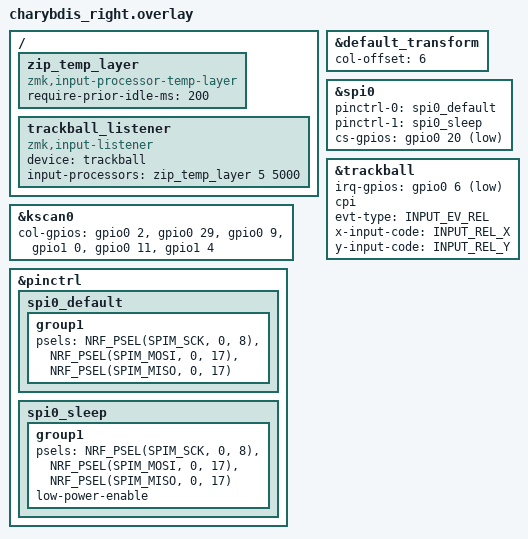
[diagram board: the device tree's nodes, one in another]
/*
 * Copyright (c) 2020 ZMK Contributors
 *
 * SPDX-License-Identifier: MIT
 */
 
#include "charybdis.dtsi"
// ★AML (オートマウスレイヤー) と KEYMAP_P マクロに必要な include を追加
#include <input/processors.dtsi>
#include <dt-bindings/zmk/matrix_transform.h>

&default_transform {
    col-offset = <6>;
};

&kscan0 {
	col-gpios
		= <&gpio0 2 (GPIO_ACTIVE_HIGH | GPIO_PULL_DOWN)>
		, <&gpio0 29 (GPIO_ACTIVE_HIGH | GPIO_PULL_DOWN)>
		, <&gpio0 9 (GPIO_ACTIVE_HIGH | GPIO_PULL_DOWN)>
		, <&gpio1 0  (GPIO_ACTIVE_HIGH | GPIO_PULL_DOWN)>
		, <&gpio0 11 (GPIO_ACTIVE_HIGH | GPIO_PULL_DOWN)>
		, <&gpio1 4  (GPIO_ACTIVE_HIGH | GPIO_PULL_DOWN)>
		;
};

// trackball bus
&spi0 {
	status = "okay";
    pinctrl-0 = <&spi0_default>;
    pinctrl-1 = <&spi0_sleep>;
    pinctrl-names = "default", "sleep";
	cs-gpios = <&gpio0 20 GPIO_ACTIVE_LOW>;
};

&pinctrl {
    spi0_default: spi0_default {
        group1 {
            psels = <NRF_PSEL(SPIM_SCK, 0, 8)>,
                    <NRF_PSEL(SPIM_MOSI, 0, 17)>,
                    <NRF_PSEL(SPIM_MISO, 0, 17)>;
        };
    };

    spi0_sleep: spi0_sleep {
        group1 {
            psels = <NRF_PSEL(SPIM_SCK, 0, 8)>,
                    <NRF_PSEL(SPIM_MOSI, 0, 17)>,
                    <NRF_PSEL(SPIM_MISO, 0, 17)>;
            low-power-enable;
        };
    };
};

&trackball {
	status = "okay"; //okay
	irq-gpios = <&gpio0 6 (GPIO_ACTIVE_LOW | GPIO_PULL_UP)>; // この行は元の設定を維持します

    /* ▼▼▼ 以下を追記します  ▼▼▼ */
    cpi = ; /* DPI (CPI) の設定。600はお好みで変更可能 */
    evt-type = <INPUT_EV_REL>; /* 必須：相対座標イベント */
    x-input-code = <INPUT_REL_X>; /* 必須：X軸のイベントコード */
    y-input-code = <INPUT_REL_Y>; /* 必須：Y軸のイベントコード */

    /* ▼▼▼ オプション：回転設定  ▼▼▼ */
    // -45度 ( = 315度) の回転を追加
    // rotation = ; // ← このプロパティは badjeff ドライバでは認識されない可能性があります

    /* 
     * badjeff ドライバは代わりに以下のプロパティを使用します。
     * -45度回転 (X/Y入れ替え + Y軸反転) が目的の場合は、
     * おそらく以下の2行のコメントを解除（行頭の // を削除）する必要があります。
     */
    // swap-xy;
    // invert-y; 
};

// ■ 修正点 2: AML (オートマウスレイヤー)
/ {
    // AMLの誤爆防止設定
    zip_temp_layer: zip_temp_layer {
        compatible = "zmk,input-processor-temp-layer";
        #input-processor-cells = <2>;
        
        // ★ご要望の機能 (キー入力直後の誤爆防止)★
        // キー入力（キープレス）後、指定した時間(ミリ秒)が経過するまで
        // トラックボールが動いてもAMLを有効にしません。
        // (例: 200ms。この値はお好みで調整してください)
        require-prior-idle-ms = <200>; 
    };

    // トラックボールが動いたらレイヤー5を5秒間有効にするリスナー
    trackball_listener: trackball_listener {
        compatible = "zmk,input-listener";
        device = <&trackball>; // &trackball と連動

        // <&zip_temp_layer [レイヤー番号] [タイムアウト(ms)]>
        // (例: レイヤー5を5000ms有効にする)
        input-processors = <&zip_temp_layer 5 5000>; 
    };
};
